# RP2040 register map
Vendor: Raspberry Pi; Series: RP; File version: 0.1
CPU: CM0PLUS r0p1, little endian, MPU, no FPU, VTOR, 2 interrupt priority bits, 32 interrupts
Registers are 32-bit, read-write, reset 0x0 unless marked. A register's access mark holds for its fields unless they carry their own. Offsets are from the block's base; [hi:lo] are bit positions; {n}, {i} and the like mark numbered series.

## WATCHDOG
Base 0x40058000
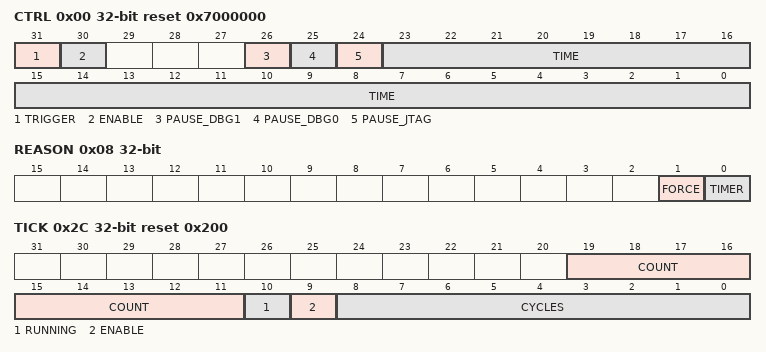
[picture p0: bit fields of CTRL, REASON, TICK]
0x00 CTRL reset 0x7000000 — Watchdog control The rst_wdsel register determines which subsystems are reset when the watchdog is triggered. The watchdog can be triggered in software.
  [31] TRIGGER write-1-clears — Trigger a watchdog reset
  [30] ENABLE — When not enabled the watchdog timer is paused
  [26] PAUSE_DBG1 — Pause the watchdog timer when processor 1 is in debug mode
  [25] PAUSE_DBG0 — Pause the watchdog timer when processor 0 is in debug mode
  [24] PAUSE_JTAG — Pause the watchdog timer when JTAG is accessing the bus fabric
  [23:0] TIME ro — Indicates the number of ticks / 2 (see errata RP2040-E1) before a watchdog reset will be triggered
0x04 LOAD — Load the watchdog timer. The maximum setting is 0xffffff which corresponds to 0xffffff / 2 ticks before triggering a watchdog reset (see errata RP2040-E1).
  [23:0] LOAD wo
0x08 REASON — Logs the reason for the last reset. Both bits are zero for the case of a hardware reset.
  [1] FORCE ro, [0] TIMER ro
{0xC+4i} SCRATCH{i} (i=0..7) — Scratch register. Information persists through soft reset of the chip.
0x2C TICK reset 0x200 — Controls the tick generator
  [19:11] COUNT ro — Count down timer: the remaining number clk_tick cycles before the next tick is generated.
  [10] RUNNING ro — Is the tick generator running?
  [9] ENABLE — start / stop tick generation
  [8:0] CYCLES — Total number of clk_tick cycles before the next tick.

## XIP_CTRL — QSPI flash execute-in-place block
Base 0x14000000
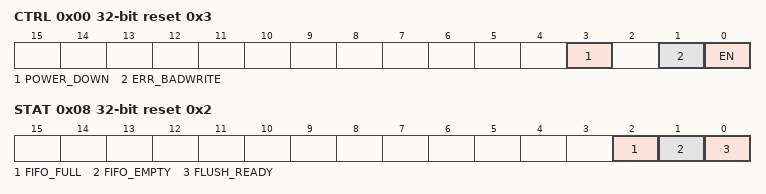
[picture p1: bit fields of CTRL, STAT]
0x00 CTRL reset 0x3 — Cache control
  [3] POWER_DOWN — When 1, the cache memories are powered down. They retain state, but can not be accessed. This reduces static power dissipation. Writing 1 to this bit forces CTRL_EN to 0, i.e. the cache cannot be enabled when powered down. Cache-as-SRAM accesses will produce a bus error response when the cache is powered down.
  [1] ERR_BADWRITE — When 1, writes to any alias other than 0x0 (caching, allocating) will produce a bus fault. When 0, these writes are silently ignored. In either case, writes to the 0x0 alias will deallocate on tag match, as usual.
  [0] EN — When 1, enable the cache. When the cache is disabled, all XIP accesses will go straight to the flash, without querying the cache. When enabled, cacheable XIP accesses will query the cache, and the flash will not be accessed if the tag matches and the valid bit is set. If the cache is enabled, cache-as-SRAM accesses have no effect on the cache data RAM, and will produce a bus error response.
0x04 FLUSH — Cache Flush control
  [0] FLUSH write-1-clears — Write 1 to flush the cache. This clears the tag memory, but the data memory retains its contents. (This means cache-as-SRAM contents is not affected by flush or reset.) Reading will hold the bus (stall the processor) until the flush completes. Alternatively STAT can be polled until completion.
0x08 STAT reset 0x2 — Cache Status
  [2] FIFO_FULL ro — When 1, indicates the XIP streaming FIFO is completely full. The streaming FIFO is 2 entries deep, so the full and empty flag allow its level to be ascertained.
  [1] FIFO_EMPTY ro — When 1, indicates the XIP streaming FIFO is completely empty.
  [0] FLUSH_READY ro — Reads as 0 while a cache flush is in progress, and 1 otherwise. The cache is flushed whenever the XIP block is reset, and also when requested via the FLUSH register.
0x0C CTR_HIT — Cache Hit counter
  [31:0] CTR_HIT write-1-clears — A 32 bit saturating counter that increments upon each cache hit, i.e. when an XIP access is serviced directly from cached data. Write any value to clear.
0x10 CTR_ACC — Cache Access counter
  [31:0] CTR_ACC write-1-clears — A 32 bit saturating counter that increments upon each XIP access, whether the cache is hit or not. This includes noncacheable accesses. Write any value to clear.
0x14 STREAM_ADDR — FIFO stream address
  [31:2] STREAM_ADDR — The address of the next word to be streamed from flash to the streaming FIFO. Increments automatically after each flash access. Write the initial access address here before starting a streaming read.
0x18 STREAM_CTR — FIFO stream control
  [21:0] STREAM_CTR — Write a nonzero value to start a streaming read. This will then progress in the background, using flash idle cycles to transfer a linear data block from flash to the streaming FIFO. Decrements automatically (1 at a time) as the stream progresses, and halts on reaching 0. Write 0 to halt an in-progress stream, and discard any in-flight read, so that a new stream can immediately be started (after draining the FIFO and reinitialising STREAM_ADDR)
0x1C STREAM_FIFO — FIFO stream data
  [31:0] STREAM_FIFO ro read-modifies — Streamed data is buffered here, for retrieval by the system DMA. This FIFO can also be accessed via the XIP_AUX slave, to avoid exposing the DMA to bus stalls caused by other XIP traffic.

## XOSC — Controls the crystal oscillator
Base 0x40024000
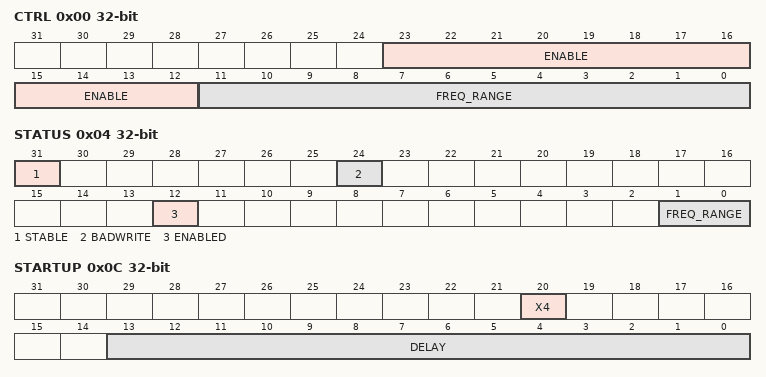
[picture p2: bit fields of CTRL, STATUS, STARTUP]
0x00 CTRL — Crystal Oscillator Control
  [23:12] ENABLE — On power-up this field is initialised to DISABLE and the chip runs from the ROSC. If the chip has subsequently been programmed to run from the XOSC then setting this field to DISABLE may lock-up the chip. If this is a concern then run the clk_ref from the ROSC and enable the clk_sys RESUS feature. The 12-bit code is intended to give some protection against accidental writes. An invalid setting will enable the oscillator.
    0xD1E=DISABLE; 0xFAB=ENABLE
  [11:0] FREQ_RANGE — Frequency range. This resets to 0xAA0 and cannot be changed.
    0xAA0=1_15MHZ
0x04 STATUS — Crystal Oscillator Status
  [31] STABLE ro — Oscillator is running and stable
  [24] BADWRITE write-1-clears — An invalid value has been written to CTRL_ENABLE or CTRL_FREQ_RANGE or DORMANT
  [12] ENABLED ro — Oscillator is enabled but not necessarily running and stable, resets to 0
  [1:0] FREQ_RANGE ro — The current frequency range setting, always reads 0
    0=1_15MHZ
0x08 DORMANT reset not defined — Crystal Oscillator pause control
  [31:0] DORMANT — This is used to save power by pausing the XOSC On power-up this field is initialised to WAKE An invalid write will also select WAKE WARNING: stop the PLLs before selecting dormant mode WARNING: setup the irq before selecting dormant mode
    0x636F6D61=DORMANT; 0x77616B65=WAKE
0x0C STARTUP — Controls the startup delay
  [20] X4 — Multiplies the startup_delay by 4. This is of little value to the user given that the delay can be programmed directly.
  [13:0] DELAY — in multiples of 256*xtal_period. The reset value of 0xc4 corresponds to approx 50 000 cycles.
0x1C COUNT — A down counter running at the xosc frequency which counts to zero and stops. To start the counter write a non-zero value. Can be used for short software pauses when setting up time sensitive hardware.
  [7:0] COUNT

## VIRTUAL
Base 0x00000000
0x00 DUMMY — Dummy register for schema compliance
  [31:0] DUMMY ro
